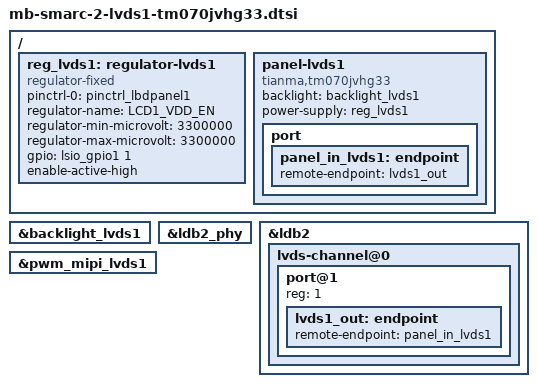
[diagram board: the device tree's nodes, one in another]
// SPDX-License-Identifier: (GPL-2.0-or-later OR MIT)
/*
 * Copyright 2018-2022 TQ-Systems GmbH
 * Author: Alexander Stein <linux@ew.tq-group.com>
 */

/ {
	reg_lvds1: regulator-lvds1 {
		compatible = "regulator-fixed";
		pinctrl-names = "default";
		pinctrl-0 = <&pinctrl_lbdpanel1>;
		regulator-name = "LCD1_VDD_EN";
		regulator-min-microvolt = <3300000>;
		regulator-max-microvolt = <3300000>;
		gpio = <&lsio_gpio1 1 GPIO_ACTIVE_HIGH>;
		enable-active-high;
	};

	panel-lvds1 {
		compatible = "tianma,tm070jvhg33";
		backlight = <&backlight_lvds1>;
		power-supply = <&reg_lvds1>;
		status = "okay";

		port {
			panel_in_lvds1: endpoint {
				remote-endpoint = <&lvds1_out>;
			};
		};
	};
};

&backlight_lvds1 {
	status = "okay";
};

&ldb2_phy {
	status = "okay";
};

&ldb2 {
	status = "okay";

	lvds-channel@0 {
		status = "okay";

		port@1 {
			reg = <1>;

			lvds1_out: endpoint {
				remote-endpoint = <&panel_in_lvds1>;
			};
		};
	};
};

&pwm_mipi_lvds1 {
	status = "okay";
};
